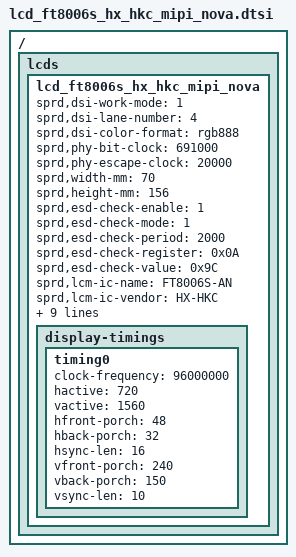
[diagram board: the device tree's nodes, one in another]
/ { lcds {
	lcd_ft8006s_hx_hkc_mipi_nova: lcd_ft8006s_hx_hkc_mipi_nova {

		sprd,dsi-work-mode = <1>;
		sprd,dsi-lane-number = <4>;
		sprd,dsi-color-format = "rgb888";

		sprd,phy-bit-clock = <691000>;
		sprd,phy-escape-clock = <20000>;

		sprd,width-mm = <70>;
		sprd,height-mm = <156>;

		sprd,esd-check-enable = <1>;
		sprd,esd-check-mode = <1>;
		sprd,esd-check-period = <2000>;
		sprd,esd-check-register = <0x0A>;
		sprd,esd-check-value = <0x9C>;
		
		sprd,lcm-ic-name = "FT8006S-AN";
		sprd,lcm-ic-vendor = "HX-HKC";
		sprd,lcm-ic-inch = "6.3";
		
		sprd,reset-on-sequence = <1 10>, <0 10>, <1 50>;
		sprd,reset-off-sequence = <1 5>;

		sprd,initial-command = [				
			//-------------  Display Initial Code Setting  -------------------------
			//Stop reload
			23 00 00 02 41 5A

			//SPI Not LoadFinish
			29 00 00 03 41 5A 24
			23 00 00 02 90 5A

			//VCOM
			//        29 00 00 03 41 5A 03
			//        29 00 00 03 80 25 01
			//----------------------LCD initial code start----------------------//
			//Blank 8
			29 00 00 03 41 5A 08
			29 00 00 05 80 C8 2C 11 00
			//Blank 9
			29 00 00 03 41 5A 09
			29 00 00 11 80 00 00 00 00 60 C5 4A 01 40 A0 0C 82 20 08 F0 03
			29 00 00 11 90 99 24 42 0A E3 91 80 F0 D6 C3 70 D8 2A 21 00 00
			29 00 00 11 A0 01 55 55 00 A0 4D 06 11 0D 60 5A FF FF 03 A5 E6
			29 00 00 11 B0 08 C9 16 64 0B 00 00 11 01 60 00 FF FF 03 FF 34
			29 00 00 09 C0 0C 3F 1F 9F 0F 00 08 00
			//Blank 10
			29 00 00 03 41 5A 0A
			29 00 00 11 80 FF 94 29 03 00 19 2A 3E 52 64 6B 9B 82 B5 87 57
			29 00 00 11 90 88 5B 57 47 36 26 17 0B 00 19 2A 3E 52 64 6B 9B
			29 00 00 0E A0 82 B5 87 57 88 5B 57 47 36 26 17 0B 00
			//Blank 11
			29 00 00 03 41 5A 0B
			29 00 00 11 80 00 00 00 00 00 00 A0 47 00 00 00 00 00 00 B0 23
			29 00 00 03 90 15 00
			//Blank 12
			29 00 00 03 41 5A 0C
			29 00 00 11 80 BA 68 68 C1 B0 75 B0 04 00 60 15 00 50 15 56 51
			29 00 00 11 90 15 55 61 15 00 60 15 00 50 15 56 51 15 55 61 95
			29 00 00 11 A0 AB 18 00 05 00 05 00 05 00 49 29 84 52 01 09 00
			29 00 00 03 B0 00 00
			//Blank 13
			29 00 00 03 41 5A 0D
			29 00 00 10 80 F0 B1 71 EF 4B C0 80 5A 00 0E 00 C0 12 00 AF
			//Blank 14
			29 00 00 03 41 5A 0E
			29 00 00 0A 80 FF 00 55 55 23 98 76 07 1C
			//Blank 15
			29 00 00 03 41 5A 0F
			29 00 00 11 80 D1 07 70 C0 12 20 64 08 52 51 58 49 03 52 4C 4C
			29 00 00 11 90 68 68 68 4C 4C 7C 14 00 20 06 C2 00 04 06 0C 40
			29 00 00 05 A0 00 92 00 04
			//Blank 16
			29 00 00 03 41 5A 10
			29 00 00 11 80 00 00 03 E7 1F 17 00 48 70 42 D0 18 30 88 41 8A
			29 00 00 10 90 39 28 A9 C5 9A 7B F0 07 7E E0 07 7E 20 10 00
			//Blank 17
			29 00 00 03 41 5A 11
			29 00 00 11 80 49 77 03 00 CA F3 FF 83 30 08 C4 06 A1 D8 24 18
			29 00 00 11 90 30 C6 66 C1 80 31 15 CB E5 D2 68 6C 36 1D 04 08
			29 00 00 11 A0 5A D8 88 60 B0 81 40 1A 1B 48 63 03 B9 00 1C 80
			29 00 00 11 B0 50 30 00 E0 E1 01 00 28 0E 06 43 55 55 55 55 55
			29 00 00 11 C0 95 88 88 88 88 88 88 08 86 C6 E3 81 00 20 00 21
			29 00 00 11 D0 42 88 00 00 00 00 00 00 00 31 04 41 06 00 00 00
			29 00 00 11 E0 00 92 04 00 92 04 00 00 00 00 92 04 00 85 11 0C
			29 00 00 10 F0 00 00 40 00 00 00 00 5E 4A 55 79 00 08 31 08
			//Blank 18
			29 00 00 03 41 5A 12
			29 00 00 11 80 00 00 00 00 00 02 03 00 00 00 00 02 03 00 41 37
			29 00 00 11 90 F1 E7 00 00 00 00 00 00 00 00 00 00 00 2D 23 05
			29 00 00 08 A0 FB 08 2D 23 05 FB 0C
			//Blank 19
			29 00 00 03 41 5A 13
			29 00 00 11 80 FD 0F 00 0C 00 00 00 A0 01 08 01 1C 44 0C CE E7
			29 00 00 11 90 62 0E 24 98 AC 21 01 00 D0 93 24 49 06 18 88 13
			29 00 00 11 A0 88 13 88 13 9F B8 8B 58 02 88 13 88 13 58 02 00
			29 00 00 0C B0 00 00 00 00 00 00 00 00 00 1B 10
			//Blank 20
			29 00 00 03 41 5A 14
			29 00 00 11 80 01 02 41 36 E9 EF F7 FB FD 7E 00 00 00 86 C5 87
			29 00 00 11 90 C7 43 20 36 3C 1E 02 DB 90 4E 13 D8 88 74 9A 00
			29 00 00 11 A0 00 00 00 00 00 00 00 00 00 00 00 00 00 00 00 00
			29 00 00 11 B0 00 00 00 00 00 00 00 00 00 DC B0 0D 2B 00 40 A1
			29 00 00 11 C0 50 78 17 9E F4 90 51 1C 6F C2 93 1E 32 8A E3 3D
			29 00 00 11 D0 78 D2 43 46 71 BC 05 4F 7A C8 28 8E 77 E0 49 0F
			29 00 00 11 E0 19 C5 F1 06 3C E9 21 A3 38 5E 80 27 3D 64 14 C7
			29 00 00 11 F0 2B F0 A4 87 8C E2 18 01 BF 5F 08 00 00 00 00 00
			//Blank 21
			29 00 00 03 41 5A 15
			29 00 00 11 80 00 00 00 00 00 00 00 00 00 00 00 00 52 D9 E0 F7
			29 00 00 11 90 A3 00 0C CB 03 EA 49 03 00 00 F6 80 7A D2 00 00
			29 00 00 11 A0 00 00 00 00 00 00 00 00 00 00 00 00 00 00 00 00
			29 00 00 11 B0 00 00 00 00 00 00 00 00 00 00 00 00 00 D3 34 CD
			29 00 00 11 C0 30 A4 40 13 04 08 84 81 DA B6 6D DB B6 35 4D D3
			29 00 00 11 D0 0C 43 C9 04 41 47 31 04 AB 6D DB B6 6D DB B6 35
			29 00 00 11 E0 CD 30 B4 40 13 14 0C C5 91 DA D6 6C DB B6 6D 5B
			29 00 00 11 F0 D3 0C 43 C8 04 41 06 21 00 AA 6D DB B6 6D 5B 00
			//Blank 22
			29 00 00 03 41 5A 16
			29 00 00 11 80 00 00 00 00 00 00 00 00 00 00 00 00 00 00 00 00
			29 00 00 07 90 00 00 00 00 F0 20
			//Blank 24
			29 00 00 03 41 5A 18
			29 00 00 11 80 04 FF 00 80 80 00 04 20 00 01 08 40 00 02 10 80
			29 00 00 03 90 00 04
			//Blank 25
			29 00 00 03 41 5A 19
			29 00 00 11 80 C0 AF A3 9B 92 8D 8A 86 84 83 82 81 00 50 F6 CF
			29 00 00 11 90 FC 2F F3 EF CF BF 0F FF AF B5 71 0E 6C 4A 69 08
			29 00 00 05 A0 00 00 46 00
			//Blank 26
			29 00 00 03 41 5A 1A
			29 00 00 11 80 00 04 08 0C 00 10 14 18 1C 00 20 28 30 38 00 40
			29 00 00 11 90 48 50 58 00 60 68 70 78 00 80 88 90 98 00 A0 A8
			29 00 00 11 A0 B0 B8 00 C0 C8 D0 D8 00 E0 E8 F0 F8 00 FC FE FF
			29 00 00 11 B0 00 00 04 08 0C 00 10 14 18 1C 00 20 28 30 38 00
			29 00 00 11 C0 40 48 50 58 00 60 68 70 78 00 80 88 90 98 00 A0
			29 00 00 11 D0 A8 B0 B8 00 C0 C8 D0 D8 00 E0 E8 F0 F8 00 FC FE
			29 00 00 11 E0 FF 00 00 04 08 0C 00 10 14 18 1C 00 20 28 30 38
			29 00 00 11 F0 00 40 48 50 58 00 60 68 70 78 00 80 88 90 98 00
			//Blank 27
			29 00 00 03 41 5A 1B
			29 00 00 11 80 A0 A8 B0 B8 00 C0 C8 D0 D8 00 E0 E8 F0 F8 00 FC
			29 00 00 05 90 FE FF 00 00
			//Blank 32
			29 00 00 03 41 5A 20
			29 00 00 08 80 84 00 02 14 00 00 00
			//Blank 34
			29 00 00 03 41 5A 22
			29 00 00 0E 80 2D D3 00 55 55 55 55 55 55 55 55 9F 00
			//Blank 35
			29 00 00 03 41 5A 23
			29 00 00 11 80 00 00 00 05 00 00 00 00 00 00 00 00 00 00 00 00
			29 00 00 0D 90 FF 0F 00 00 00 03 00 00 00 FF 07 35
			//Blank 36
			29 00 00 03 41 5A 24
			29 00 00 11 80 00 03 00 FF FF 20 00 00 00 00 00 00 00 00 18 2B
			29 00 00 11 90 5A 5A 5A 55 00 00 00 00 00 00 00 00 00 00 00 00

			//----------------------LCD initial code End----------------------//

			//SPI FINISH
			23 00 00 02 42 24
			23 00 00 02 90 00
			//Blank select 2F 
			29 00 00 03 41 5A 2F
			23 00 00 02 19 01
			//INT CANCEL
			23 00 00 02 4C 03

			13 78 00 01 11
			13 14 00 01 29

			//CMD1 LEDPWM set
			29 00 00 03 51 ff 0f
			23 00 00 02 53 24
			23 00 00 02 55 00
		];
		sprd,sleep-in-command = [
			13 0A 00 01 28
			13 78 00 01 10
			13 00 00 02 17 5A
			13 96 00 02 18 5A			
		];
		sprd,sleep-out-command = [
			13 78 00 01 11
			13 14 00 01 29
		];

		display-timings {
			timing0{
				clock-frequency = <96000000>;
				hactive = <720>;
				vactive = <1560>;
				hfront-porch = <48>;
				hback-porch = <32>;
				hsync-len = <16>;
				vfront-porch = <240>;
				vback-porch = <150>;
				vsync-len = <10>;
			};
		};
	};
};};


